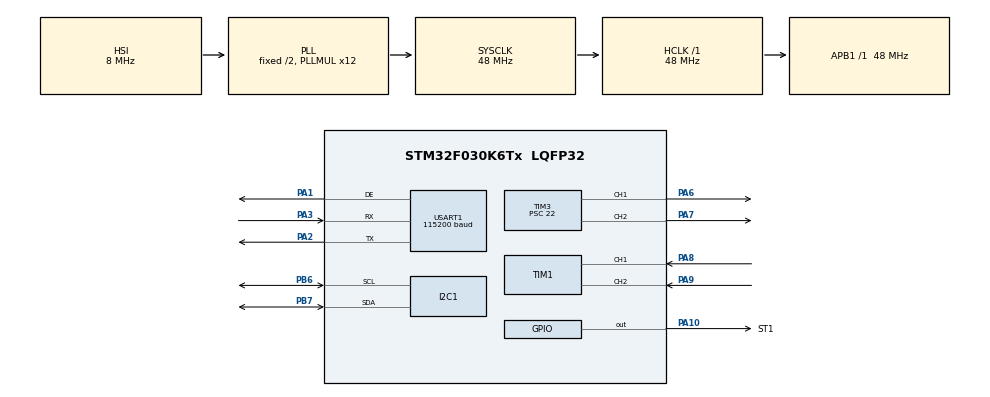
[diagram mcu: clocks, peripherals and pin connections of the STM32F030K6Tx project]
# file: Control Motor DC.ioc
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I2C1.Timing=0x00201D2B
Mcu.Family=STM32F0
Mcu.Name=STM32F030K6Tx
Mcu.Package=LQFP32
NVIC.TIM1_BRK_UP_TRG_COM_IRQn=true\:0\:0\:false\:false\:true\:true\:true\:true
NVIC.TIM1_CC_IRQn=true\:0\:0\:false\:false\:true\:true\:true\:true
NVIC.USART1_IRQn=true\:0\:0\:false\:false\:true\:true\:true\:true
PA1.Mode=Hardware Flow Control (RS485)
PA1.Signal=USART1_DE
PA10.GPIO_Label=ST1
PA10.Signal=GPIO_Output
PA13.Mode=Serial_Wire
PA13.Signal=SYS_SWDIO
PA14.Mode=Serial_Wire
PA14.Signal=SYS_SWCLK
PA2.Mode=Asynchronous
PA2.Signal=USART1_TX
PA3.Mode=Asynchronous
PA3.Signal=USART1_RX
PA6.Signal=S_TIM3_CH1
PA7.Signal=S_TIM3_CH2
PA8.Signal=S_TIM1_CH1
PA9.Signal=S_TIM1_CH2
PB6.Mode=I2C
PB6.Signal=I2C1_SCL
PB7.Mode=I2C
PB7.Signal=I2C1_SDA
ProjectManager.HeapSize=0x200
ProjectManager.StackSize=0x400
ProjectManager.TargetToolchain=MDK-ARM V5.32
RCC.AHBFreq_Value=48000000
RCC.APB1Freq_Value=48000000
RCC.APB1TimFreq_Value=48000000
RCC.HCLKFreq_Value=48000000
RCC.PLLMUL=RCC_PLL_MUL12
RCC.SYSCLKFreq_VALUE=48000000
RCC.SYSCLKSource=RCC_SYSCLKSOURCE_PLLCLK
SH.S_TIM1_CH1.0=TIM1_CH1,Encoder_Interface
SH.S_TIM1_CH2.0=TIM1_CH2,Encoder_Interface
SH.S_TIM3_CH1.0=TIM3_CH1,PWM Generation1 CH1
SH.S_TIM3_CH2.0=TIM3_CH2,PWM Generation2 CH2
TIM1.AutoReloadPreload=TIM_AUTORELOAD_PRELOAD_DISABLE
TIM1.EncoderMode=TIM_ENCODERMODE_TI12
TIM1.IC1Polarity=TIM_ICPOLARITY_RISING
TIM1.IC2Polarity=TIM_ICPOLARITY_RISING
TIM3.Channel-PWM\ Generation1\ CH1=TIM_CHANNEL_1
TIM3.Channel-PWM\ Generation2\ CH2=TIM_CHANNEL_2
TIM3.Period=100
TIM3.Prescaler=22
TIM3.Pulse-PWM\ Generation1\ CH1=0
USART1.BaudRate=115200
USART1.VirtualMode-Asynchronous=VM_ASYNC
USART1.VirtualMode-Hardware\ Flow\ Control\ (RS485)=VM_ASYNC
VP_TIM3_VS_ClockSourceINT.Mode=Internal
board=custom

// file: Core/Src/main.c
/* USER CODE BEGIN Header */
/**
  ******************************************************************************
  * @file           : main.c
  * @brief          : Main program body
  ******************************************************************************
  * @attention
  *
  * Copyright (c) 2024 STMicroelectronics.
  * All rights reserved.
  *
  * This software is licensed under terms that can be found in the LICENSE file
  * in the root directory of this software component.
  * If no LICENSE file comes with this software, it is provided AS-IS.
  *
  ******************************************************************************
  */
/* USER CODE END Header */
#include "main.h"
#include "i2c.h"
#include "tim.h"
#include "usart.h"
#include "gpio.h"

/* USER CODE BEGIN Includes */
#include "control.h"
/* USER CODE END Includes */

void SystemClock_Config(void);

int main(void)
{

  /* MCU Configuration--------------------------------------------------------*/

  /* Reset of all peripherals, Initializes the Flash interface and the Systick. */
  HAL_Init();

  /* Configure the system clock */
  SystemClock_Config();

  /* Initialize all configured peripherals */
  MX_GPIO_Init();
  MX_I2C1_Init();
  MX_TIM1_Init();
  MX_TIM3_Init();
  MX_USART1_UART_Init();
  /* USER CODE BEGIN 2 */
	init();
  /* USER CODE END 2 */

  /* Infinite loop */
  /* USER CODE BEGIN WHILE */
  while (1)
  {
		run();
    /* USER CODE END WHILE */

  }
}

void SystemClock_Config(void)
{
  RCC_OscInitTypeDef RCC_OscInitStruct = {0};
  RCC_ClkInitTypeDef RCC_ClkInitStruct = {0};
  RCC_PeriphCLKInitTypeDef PeriphClkInit = {0};

  /** Initializes the RCC Oscillators according to the specified parameters
  * in the RCC_OscInitTypeDef structure.
  */
  RCC_OscInitStruct.OscillatorType = RCC_OSCILLATORTYPE_HSI;
  RCC_OscInitStruct.HSIState = RCC_HSI_ON;
  RCC_OscInitStruct.HSICalibrationValue = RCC_HSICALIBRATION_DEFAULT;
  RCC_OscInitStruct.PLL.PLLState = RCC_PLL_ON;
  RCC_OscInitStruct.PLL.PLLSource = RCC_PLLSOURCE_HSI;
  RCC_OscInitStruct.PLL.PLLMUL = RCC_PLL_MUL12;
  RCC_OscInitStruct.PLL.PREDIV = RCC_PREDIV_DIV1;
  if (HAL_RCC_OscConfig(&RCC_OscInitStruct) != HAL_OK)
  {
    Error_Handler();
  }

  /** Initializes the CPU, AHB and APB buses clocks
  */
  RCC_ClkInitStruct.ClockType = RCC_CLOCKTYPE_HCLK|RCC_CLOCKTYPE_SYSCLK
                              |RCC_CLOCKTYPE_PCLK1;
  RCC_ClkInitStruct.SYSCLKSource = RCC_SYSCLKSOURCE_PLLCLK;
  RCC_ClkInitStruct.AHBCLKDivider = RCC_SYSCLK_DIV1;
  RCC_ClkInitStruct.APB1CLKDivider = RCC_HCLK_DIV1;

  if (HAL_RCC_ClockConfig(&RCC_ClkInitStruct, FLASH_LATENCY_1) != HAL_OK)
  {
    Error_Handler();
  }
  PeriphClkInit.PeriphClockSelection = RCC_PERIPHCLK_USART1|RCC_PERIPHCLK_I2C1;
  PeriphClkInit.Usart1ClockSelection = RCC_USART1CLKSOURCE_PCLK1;
  PeriphClkInit.I2c1ClockSelection = RCC_I2C1CLKSOURCE_HSI;
  if (HAL_RCCEx_PeriphCLKConfig(&PeriphClkInit) != HAL_OK)
  {
    Error_Handler();
  }
}

void Error_Handler(void)
{
  __disable_irq();
  while (1)
  {
  }
}
